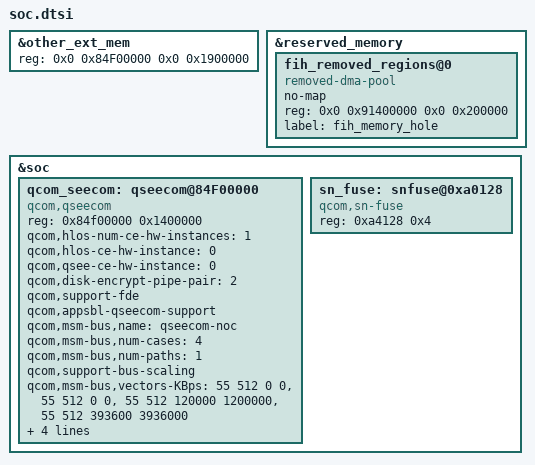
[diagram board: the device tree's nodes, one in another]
&other_ext_mem {
	reg = <0x0 0x84F00000 0x0 0x1900000>;
};

&reserved_memory {
	fih_removed_regions@0 {
		compatible = "removed-dma-pool";
		no-map;
		reg = <0x0 0x91400000 0x0 0x200000>;
		label = "fih_memory_hole";
	};
};

&soc {
	/delete-node/ qseecom@84a00000;

	qcom_seecom: qseecom@84F00000 {
		compatible = "qcom,qseecom";
		reg = <0x84f00000 0x1400000>;
		reg-names = "secapp-region";
		qcom,hlos-num-ce-hw-instances = <1>;
		qcom,hlos-ce-hw-instance = <0>;
		qcom,qsee-ce-hw-instance = <0>;
		qcom,disk-encrypt-pipe-pair = <2>;
		qcom,support-fde;
		qcom,appsbl-qseecom-support;
		qcom,msm-bus,name = "qseecom-noc";
		qcom,msm-bus,num-cases = <4>;
		qcom,msm-bus,num-paths = <1>;
		qcom,support-bus-scaling;
		qcom,msm-bus,vectors-KBps =
			<55 512 0 0>,
			<55 512 0 0>,
			<55 512 120000 1200000>,
			<55 512 393600 3936000>;
		clocks = <&gcc CRYPTO_CLK_SRC>,
			<&gcc GCC_CRYPTO_CLK>,
			<&gcc GCC_CRYPTO_AHB_CLK>,
			<&gcc GCC_CRYPTO_AXI_CLK>;
		clock-names = "core_clk_src", "core_clk",
				"iface_clk", "bus_clk";
		qcom,ce-opp-freq = <100000000>;
	};
};

&soc {
	sn_fuse: snfuse@0xa0128 {
		compatible = "qcom,sn-fuse";
		reg = <0xa4128 0x4>;
		reg-names = "sn-base";
	};
};
